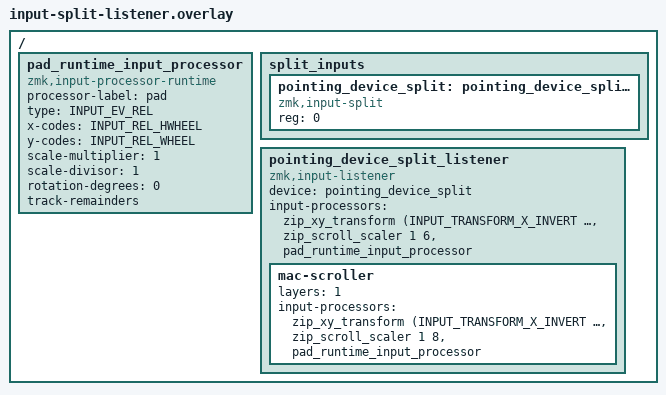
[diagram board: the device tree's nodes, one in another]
/{
    // The mini trackpad emits wheel events directly; never map these from XY again.
    pad_runtime_input_processor: pad_runtime_input_processor {
        compatible = "zmk,input-processor-runtime";
        processor-label = "pad";
        type = <INPUT_EV_REL>;
        x-codes = <INPUT_REL_HWHEEL>;
        y-codes = <INPUT_REL_WHEEL>;
        scale-multiplier = <1>;
        scale-divisor = <1>;
        rotation-degrees = <0>;
        track-remainders;
        #input-processor-cells = <0>;
    };

    split_inputs {
        #address-cells = <1>;
        #size-cells = <0>;

        pointing_device_split: pointing_device_split@0 {
            compatible = "zmk,input-split";
            reg = <0>;
        };
    };

    pointing_device_split_listener: pointing_device_split_listener {
        compatible = "zmk,input-listener";
        device = <&pointing_device_split>;
        status = "okay";
        // Windows/base path: same speed as the previous Mac setting.
        input-processors =
            <&zip_xy_transform (INPUT_TRANSFORM_X_INVERT | INPUT_TRANSFORM_Y_INVERT)>,
            <&zip_scroll_scaler 1 6>,
            <&pad_runtime_input_processor>;

        mac-scroller {
            // L1 stays active under Mac's momentary layers and Bluetooth management.
            // Override the base path: 25% slower than the previous Mac setting.
            layers = <1>;
            input-processors =
                <&zip_xy_transform (INPUT_TRANSFORM_X_INVERT | INPUT_TRANSFORM_Y_INVERT)>,
                <&zip_scroll_scaler 1 8>,
                <&pad_runtime_input_processor>;
        };
     };
};
